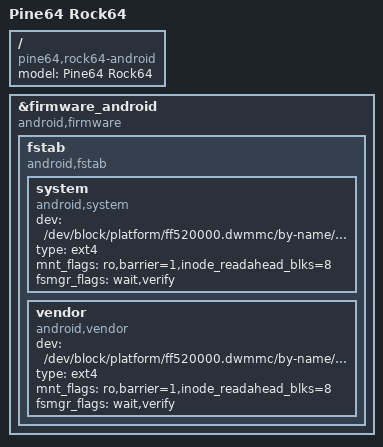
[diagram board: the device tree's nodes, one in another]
/*
 * Copyright (c) 2017 Fuzhou Rockchip Electronics Co., Ltd
 *
 * SPDX-License-Identifier: (GPL-2.0+ OR MIT)
 */

/dts-v1/;
#include "rk3328-rock64-android.dtsi"

/ {
	model = "Pine64 Rock64";
	compatible = "pine64,rock64-android", "rockchip,rk3328";
};

&firmware_android{
	compatible = "android,firmware";
	fstab {
		compatible = "android,fstab";
		system {
			compatible = "android,system";
			dev = "/dev/block/platform/ff520000.dwmmc/by-name/system";
			type = "ext4";
			mnt_flags = "ro,barrier=1,inode_readahead_blks=8";
			fsmgr_flags = "wait,verify";
		};
		vendor {
			compatible = "android,vendor";
			dev = "/dev/block/platform/ff520000.dwmmc/by-name/vendor";
			type = "ext4";
			mnt_flags = "ro,barrier=1,inode_readahead_blks=8";
			fsmgr_flags = "wait,verify";
		};
	};
};
